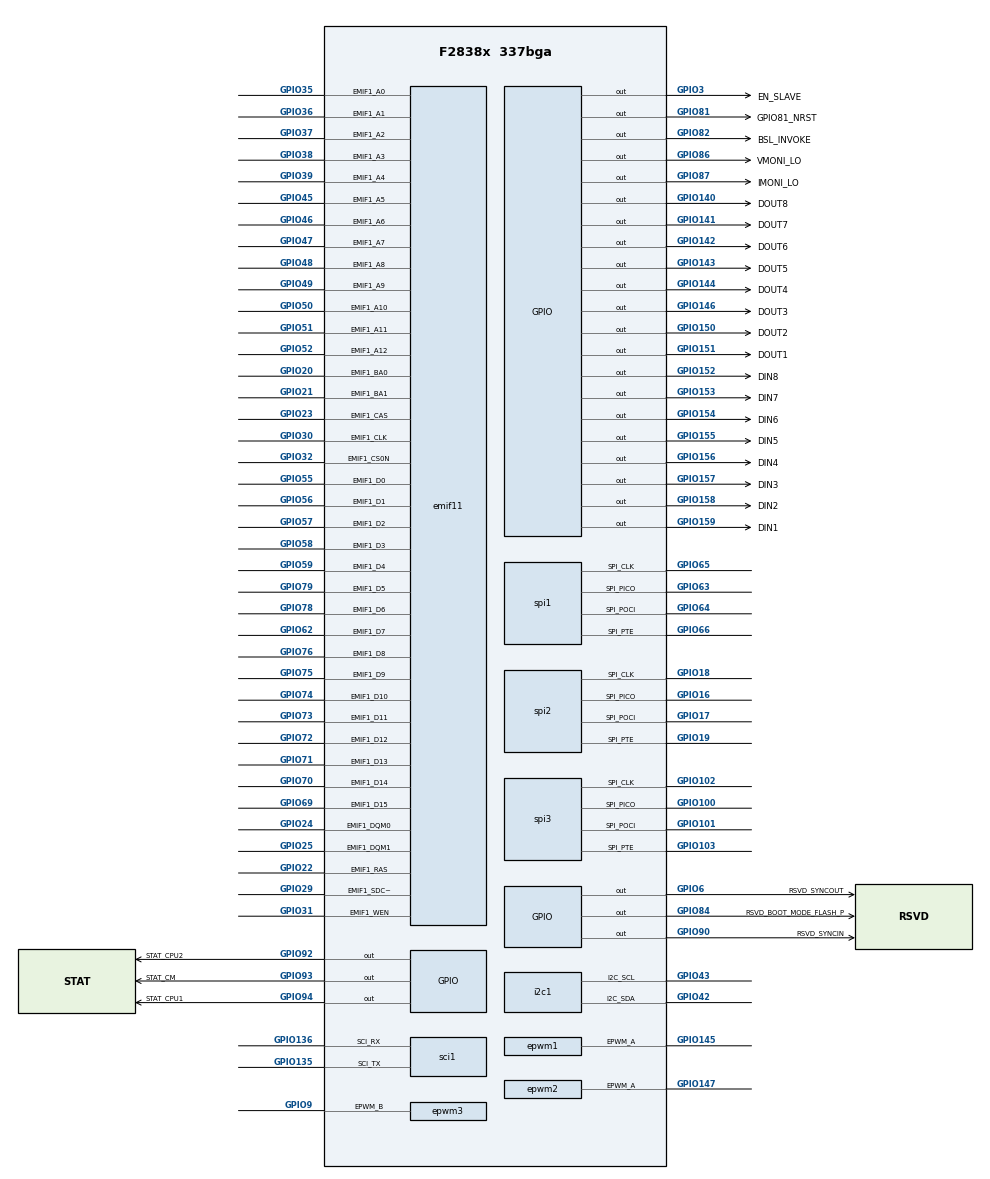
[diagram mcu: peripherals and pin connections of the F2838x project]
/**
 * @cliArgs --device "F2838x" --part "F2838x_337bga" --package "337bga" --context "CPU1" --product "C2000WARE@5.04.00.00"
 * @versions {"tool":"1.21.0+3721"}
 */

/**
 * Import the modules used in this configuration.
 */
const adc              = scripting.addModule("/driverlib/adc.js");
const adc1             = adc.addInstance();
const adc2             = adc.addInstance();
const adc3             = adc.addInstance();
const adc4             = adc.addInstance();
const cputimer         = scripting.addModule("/driverlib/cputimer.js", {}, false);
const cputimer1        = cputimer.addInstance();
const dac              = scripting.addModule("/driverlib/dac.js", {}, false);
const dac1             = dac.addInstance();
const dac2             = dac.addInstance();
const dac3             = dac.addInstance();
const dma              = scripting.addModule("/driverlib/dma.js", {}, false);
const dma1             = dma.addInstance();
const dma2             = dma.addInstance();
const dma3             = dma.addInstance();
const dma4             = dma.addInstance();
const dma5             = dma.addInstance();
const dma6             = dma.addInstance();
const ecap             = scripting.addModule("/driverlib/ecap.js", {}, false);
const ecap1            = ecap.addInstance();
const emif1            = scripting.addModule("/driverlib/emif1.js", {}, false);
const emif11           = emif1.addInstance();
const epwm             = scripting.addModule("/driverlib/epwm.js", {}, false);
const epwm1            = epwm.addInstance();
const epwm2            = epwm.addInstance();
const epwm3            = epwm.addInstance();
const flash            = scripting.addModule("/driverlib/flash.js", {}, false);
const flash1           = flash.addInstance();
const gpio             = scripting.addModule("/driverlib/gpio.js", {}, false);
const gpio1            = gpio.addInstance();
const gpio2            = gpio.addInstance();
const gpio3            = gpio.addInstance();
const gpio4            = gpio.addInstance();
const gpio5            = gpio.addInstance();
const gpio6            = gpio.addInstance();
const gpio7            = gpio.addInstance();
const gpio8            = gpio.addInstance();
const gpio9            = gpio.addInstance();
const gpio10           = gpio.addInstance();
const gpio11           = gpio.addInstance();
const gpio12           = gpio.addInstance();
const gpio13           = gpio.addInstance();
const gpio14           = gpio.addInstance();
const gpio15           = gpio.addInstance();
const gpio16           = gpio.addInstance();
const gpio17           = gpio.addInstance();
const gpio18           = gpio.addInstance();
const gpio19           = gpio.addInstance();
const gpio20           = gpio.addInstance();
const gpio21           = gpio.addInstance();
const gpio22           = gpio.addInstance();
const gpio23           = gpio.addInstance();
const gpio24           = gpio.addInstance();
const gpio25           = gpio.addInstance();
const gpio26           = gpio.addInstance();
const gpio27           = gpio.addInstance();
const i2c              = scripting.addModule("/driverlib/i2c.js", {}, false);
const i2c1             = i2c.addInstance();
const inputxbar_input  = scripting.addModule("/driverlib/inputxbar_input.js", {}, false);
const inputxbar_input1 = inputxbar_input.addInstance();
const ipc              = scripting.addModule("/driverlib/ipc.js");
const sci              = scripting.addModule("/driverlib/sci.js", {}, false);
const sci1             = sci.addInstance();
const spi              = scripting.addModule("/driverlib/spi.js", {}, false);
const spi1             = spi.addInstance();
const spi2             = spi.addInstance();
const spi3             = spi.addInstance();
const sync             = scripting.addModule("/driverlib/sync.js");

/**
 * Write custom configuration values to the imported modules.
 */
adc.synchronousModeCheck = true;

adc1.$name                    = "ADCA_AIN1";
adc1.soc0Channel              = "ADC_CH_ADCIN4";
adc1.adcClockPrescaler        = "ADC_CLK_DIV_4_0";
adc1.soc0SampleWindow         = 64;
adc1.enabledSOCs              = ["ADC_SOC_NUMBER0","ADC_SOC_NUMBER1","ADC_SOC_NUMBER2","ADC_SOC_NUMBER3"];
adc1.soc1SampleWindow         = 64;
adc1.soc0Trigger              = "ADC_TRIGGER_EPWM1_SOCA";
adc1.soc1Trigger              = "ADC_TRIGGER_EPWM1_SOCA";
adc1.soc2Trigger              = "ADC_TRIGGER_EPWM1_SOCA";
adc1.soc2SampleWindow         = 64;
adc1.soc3SampleWindow         = 64;
adc1.soc3Trigger              = "ADC_TRIGGER_EPWM1_SOCA";
adc1.interruptPulseMode       = "ADC_PULSE_END_OF_CONV";
adc1.enabledInts              = ["ADC_INT_NUMBER1"];
adc1.enableInterrupt1         = true;
adc1.interrupt1SOCSource      = "ADC_SOC_NUMBER3";
adc1.registerInterrupts       = ["1"];
adc1.adcInt1.interruptHandler = "INT_CPU1_ADCA_1_ISR";
adc1.adcInt1.enableInterrupt  = true;

adc2.$name             = "ADCB_AIN2";
adc2.adcBase           = "ADCB_BASE";
adc2.adcClockPrescaler = "ADC_CLK_DIV_4_0";
adc2.soc0Channel       = "ADC_CH_ADCIN4";
adc2.soc0Trigger       = "ADC_TRIGGER_EPWM1_SOCA";
adc2.soc0SampleWindow  = 64;
adc2.enabledSOCs       = ["ADC_SOC_NUMBER0","ADC_SOC_NUMBER1","ADC_SOC_NUMBER2","ADC_SOC_NUMBER3"];
adc2.soc1Channel       = "ADC_CH_ADCIN4";
adc2.soc1SampleWindow  = 64;
adc2.soc1Trigger       = "ADC_TRIGGER_EPWM1_SOCA";
adc2.soc2Channel       = "ADC_CH_ADCIN4";
adc2.soc2Trigger       = "ADC_TRIGGER_EPWM1_SOCA";
adc2.soc2SampleWindow  = 64;
adc2.soc3Trigger       = "ADC_TRIGGER_EPWM1_SOCA";
adc2.soc3SampleWindow  = 64;
adc2.soc3Channel       = "ADC_CH_ADCIN4";

adc3.$name             = "ADCC_AIN3";
adc3.adcBase           = "ADCC_BASE";
adc3.adcClockPrescaler = "ADC_CLK_DIV_4_0";
adc3.soc0Channel       = "ADC_CH_ADCIN4";
adc3.enabledSOCs       = ["ADC_SOC_NUMBER0","ADC_SOC_NUMBER1","ADC_SOC_NUMBER2","ADC_SOC_NUMBER3"];
adc3.soc0Trigger       = "ADC_TRIGGER_EPWM1_SOCA";
adc3.soc0SampleWindow  = 64;
adc3.soc1Channel       = "ADC_CH_ADCIN4";
adc3.soc1Trigger       = "ADC_TRIGGER_EPWM1_SOCA";
adc3.soc1SampleWindow  = 64;
adc3.soc2Trigger       = "ADC_TRIGGER_EPWM1_SOCA";
adc3.soc2SampleWindow  = 64;
adc3.soc2Channel       = "ADC_CH_ADCIN4";
adc3.soc3Channel       = "ADC_CH_ADCIN4";
adc3.soc3SampleWindow  = 64;
adc3.soc3Trigger       = "ADC_TRIGGER_EPWM1_SOCA";

adc4.$name             = "RSVD_ADCD";
adc4.adcBase           = "ADCD_BASE";
adc4.adcClockPrescaler = "ADC_CLK_DIV_4_0";
adc4.soc0Channel       = "ADC_CH_ADCIN4";
adc4.enabledSOCs       = ["ADC_SOC_NUMBER0","ADC_SOC_NUMBER1","ADC_SOC_NUMBER2","ADC_SOC_NUMBER3"];
adc4.soc0SampleWindow  = 64;
adc4.soc0Trigger       = "ADC_TRIGGER_EPWM1_SOCA";
adc4.soc1Channel       = "ADC_CH_ADCIN4";
adc4.soc1Trigger       = "ADC_TRIGGER_EPWM1_SOCA";
adc4.soc1SampleWindow  = 64;
adc4.soc2Channel       = "ADC_CH_ADCIN4";
adc4.soc2SampleWindow  = 64;
adc4.soc2Trigger       = "ADC_TRIGGER_EPWM1_SOCA";
adc4.soc3Channel       = "ADC_CH_ADCIN4";
adc4.soc3Trigger       = "ADC_TRIGGER_EPWM1_SOCA";
adc4.soc3SampleWindow  = 64;

const divider11       = system.clockTree["LOSPCP"];
divider11.divideValue = 1;

cputimer1.emulationMode  = "CPUTIMER_EMULATIONMODE_RUNFREE";
cputimer1.timerPrescaler = 3;
cputimer1.timerPeriod    = 50000000;
cputimer1.startTimer     = true;
cputimer1.$name          = "SWTIRMER";

dac1.$name = "DACA_AOUT1";

dac2.$name   = "DACB_AOUT2";
dac2.dacBase = "DACB_BASE";

dac3.$name            = "RSVD_DACC";
dac3.dacBase          = "DACC_BASE";
dac3.enableOutput     = true;
dac3.referenceVoltage = "DAC_REF_ADC_VREFHI";

dma1.$name = "DMA_SPIC_TX";

dma2.$name   = "DMA_SPIC_RX";
dma2.dmaBase = "DMA_CH2_BASE";

dma3.$name   = "DMA_SPIB_TX";
dma3.dmaBase = "DMA_CH3_BASE";

dma4.$name   = "DMA_SPIB_RX";
dma4.dmaBase = "DMA_CH4_BASE";

dma5.$name   = "DMA_SPIA_TX";
dma5.dmaBase = "DMA_CH5_BASE";

dma6.$name   = "DMA_SPIA_RX";
dma6.dmaBase = "DMA_CH6_BASE";

ecap1.ecapInput = "ECAP_INPUT_GPIO8";
ecap1.$name     = "ECAP1_ACFAIL";

emif11.enableCS3                    = false;
emif11.enableCS4                    = false;
emif11.useCase                      = "CUSTOM";
emif11.useInterfacePins             = ["EMIF1_A0","EMIF1_A1","EMIF1_A10","EMIF1_A11","EMIF1_A12","EMIF1_A2","EMIF1_A3","EMIF1_A4","EMIF1_A5","EMIF1_A6","EMIF1_A7","EMIF1_A8","EMIF1_A9","EMIF1_BA0","EMIF1_BA1","EMIF1_CAS","EMIF1_CLK","EMIF1_CS0n","EMIF1_D0","EMIF1_D1","EMIF1_D10","EMIF1_D11","EMIF1_D12","EMIF1_D13","EMIF1_D14","EMIF1_D15","EMIF1_D2","EMIF1_D3","EMIF1_D4","EMIF1_D5","EMIF1_D6","EMIF1_D7","EMIF1_D8","EMIF1_D9","EMIF1_DQM0","EMIF1_DQM1","EMIF1_RAS","EMIF1_SDCKE","EMIF1_WEn"];
emif11.cs0Narrow                    = "EMIF_SYNC_NARROW_MODE_TRUE";
emif11.enableCS2                    = false;
emif11.$name                        = "EMIF1_SDRAM";
emif11.emif1.$assign                = "EMIF1";
emif11.emif1.emif1_cs0nPin.$assign  = "GPIO32";
emif11.emif1.emif1_sdckePin.$assign = "GPIO29";
emif11.emif1.emif1_clkPin.$assign   = "GPIO30";
emif11.emif1.emif1_wenPin.$assign   = "GPIO31";
emif11.emif1.emif1_casPin.$assign   = "GPIO23";
emif11.emif1.emif1_rasPin.$assign   = "GPIO22";
emif11.emif1.emif1_dqm0Pin.$assign  = "GPIO24";
emif11.emif1.emif1_dqm1Pin.$assign  = "GPIO25";
emif11.emif1.emif1_ba0Pin.$assign   = "GPIO20";
emif11.emif1.emif1_ba1Pin.$assign   = "GPIO21";
emif11.emif1.emif1_a0Pin.$assign    = "GPIO35";
emif11.emif1.emif1_a1Pin.$assign    = "GPIO36";
emif11.emif1.emif1_a2Pin.$assign    = "GPIO37";
emif11.emif1.emif1_a3Pin.$assign    = "GPIO38";
emif11.emif1.emif1_a4Pin.$assign    = "GPIO39";
emif11.emif1.emif1_a5Pin.$assign    = "GPIO45";
emif11.emif1.emif1_a6Pin.$assign    = "GPIO46";
emif11.emif1.emif1_a7Pin.$assign    = "GPIO47";
emif11.emif1.emif1_a8Pin.$assign    = "GPIO48";
emif11.emif1.emif1_a9Pin.$assign    = "GPIO49";
emif11.emif1.emif1_a10Pin.$assign   = "GPIO50";
emif11.emif1.emif1_a11Pin.$assign   = "GPIO51";
emif11.emif1.emif1_a12Pin.$assign   = "GPIO52";
emif11.emif1.emif1_d0Pin.$assign    = "GPIO55";
emif11.emif1.emif1_d1Pin.$assign    = "GPIO56";
emif11.emif1.emif1_d2Pin.$assign    = "GPIO57";
emif11.emif1.emif1_d3Pin.$assign    = "GPIO58";
emif11.emif1.emif1_d4Pin.$assign    = "GPIO59";
emif11.emif1.emif1_d5Pin.$assign    = "GPIO79";
emif11.emif1.emif1_d6Pin.$assign    = "GPIO78";
emif11.emif1.emif1_d7Pin.$assign    = "GPIO62";
emif11.emif1.emif1_d8Pin.$assign    = "GPIO76";
emif11.emif1.emif1_d9Pin.$assign    = "GPIO75";
emif11.emif1.emif1_d10Pin.$assign   = "GPIO74";
emif11.emif1.emif1_d11Pin.$assign   = "GPIO73";
emif11.emif1.emif1_d12Pin.$assign   = "GPIO72";
emif11.emif1.emif1_d13Pin.$assign   = "GPIO71";
emif11.emif1.emif1_d14Pin.$assign   = "GPIO70";
emif11.emif1.emif1_d15Pin.$assign   = "GPIO69";

epwm1.useCase                = "CUSTOM";
epwm1.useInterfacePins       = ["EPWM#A"];
epwm1.$name                  = "MEAS_CNV";
epwm1.epwm.$assign           = "EPWM1";
epwm1.epwm.epwm_aPin.$assign = "GPIO145";

epwm2.useCase                = "CUSTOM";
epwm2.useInterfacePins       = ["EPWM#A"];
epwm2.$name                  = "CVAD_CNV";
epwm2.epwm.$assign           = "EPWM2";
epwm2.epwm.epwm_aPin.$assign = "GPIO147";

epwm3.$name                  = "PWM5_OFFPWM";
epwm3.useCase                = "CUSTOM";
epwm3.useInterfacePins       = ["EPWM#B"];
epwm3.epwm.$assign           = "EPWM5";
epwm3.epwm.epwm_bPin.$assign = "GPIO9";

flash1.$name = "FMC_CPU1";

gpio1.$name           = "RSVD_BOOT_MODE_FLASH_P";
gpio1.gpioPin.$assign = "GPIO84";

gpio2.$name           = "RSVD_SYNCIN";
gpio2.gpioPin.$assign = "GPIO90";

gpio3.$name           = "RSVD_SYNCOUT";
gpio3.gpioPin.$assign = "GPIO6";

gpio4.$name           = "DIN1";
gpio4.gpioPin.$assign = "GPIO159";

gpio5.$name           = "DIN2";
gpio5.gpioPin.$assign = "GPIO158";

gpio6.$name           = "DIN3";
gpio6.gpioPin.$assign = "GPIO157";

gpio7.$name           = "DIN4";
gpio7.gpioPin.$assign = "GPIO156";

gpio8.$name           = "DIN5";
gpio8.gpioPin.$assign = "GPIO155";

gpio9.$name           = "DIN6";
gpio9.gpioPin.$assign = "GPIO154";

gpio10.$name           = "DIN7";
gpio10.gpioPin.$assign = "GPIO153";

gpio11.$name           = "DIN8";
gpio11.gpioPin.$assign = "GPIO152";

gpio12.$name           = "DOUT1";
gpio12.direction       = "GPIO_DIR_MODE_OUT";
gpio12.gpioPin.$assign = "GPIO151";

gpio13.$name           = "DOUT2";
gpio13.direction       = "GPIO_DIR_MODE_OUT";
gpio13.gpioPin.$assign = "GPIO150";

gpio14.$name           = "DOUT3";
gpio14.direction       = "GPIO_DIR_MODE_OUT";
gpio14.gpioPin.$assign = "GPIO146";

gpio15.$name           = "DOUT4";
gpio15.direction       = "GPIO_DIR_MODE_OUT";
gpio15.gpioPin.$assign = "GPIO144";

gpio16.$name           = "DOUT5";
gpio16.direction       = "GPIO_DIR_MODE_OUT";
gpio16.gpioPin.$assign = "GPIO143";

gpio17.$name           = "DOUT6";
gpio17.direction       = "GPIO_DIR_MODE_OUT";
gpio17.gpioPin.$assign = "GPIO142";

gpio18.$name           = "DOUT7";
gpio18.gpioPin.$assign = "GPIO141";

gpio19.$name           = "DOUT8";
gpio19.direction       = "GPIO_DIR_MODE_OUT";
gpio19.gpioPin.$assign = "GPIO140";

gpio20.direction         = "GPIO_DIR_MODE_OUT";
gpio20.$name             = "EN_SLAVE";
gpio20.writeInitialValue = true;
gpio20.gpioPin.$assign   = "GPIO3";

gpio21.$name             = "VMONI_LO";
gpio21.direction         = "GPIO_DIR_MODE_OUT";
gpio21.writeInitialValue = true;
gpio21.gpioPin.$assign   = "GPIO86";

gpio22.$name             = "IMONI_LO";
gpio22.direction         = "GPIO_DIR_MODE_OUT";
gpio22.writeInitialValue = true;
gpio22.gpioPin.$assign   = "GPIO87";

gpio23.$name           = "STAT_CPU1";
gpio23.gpioPin.$assign = "GPIO94";

gpio24.$name           = "STAT_CPU2";
gpio24.direction       = "GPIO_DIR_MODE_OUT";
gpio24.controllerCore  = "GPIO_CORE_CPU2";
gpio24.gpioPin.$assign = "GPIO92";

gpio25.$name           = "STAT_CM";
gpio25.direction       = "GPIO_DIR_MODE_OUT";
gpio25.gpioPin.$assign = "GPIO93";

gpio26.$name           = "BSL_INVOKE";
gpio26.direction       = "GPIO_DIR_MODE_OUT";
gpio26.gpioPin.$assign = "GPIO82";

gpio27.$name           = "GPIO81_NRST";
gpio27.gpioPin.$assign = "GPIO81";

i2c1.$name                  = "I2CA_M";
i2c1.i2c.$assign            = "I2CA";
i2c1.i2c.i2c_sdaPin.$assign = "GPIO42";
i2c1.i2c.i2c_sclPin.$assign = "GPIO43";

inputxbar_input1.$name         = "myINPUTXBARINPUT0";
inputxbar_input1.inputxbarGpio = "GPIO90";

ipc.ipcRegisterFlag = ["IPC_FLAG31"];

sci1.$name                 = "SCI_BOOT_DEBUG";
sci1.sci.$assign           = "SCIA";
sci1.sci.sci_rxPin.$assign = "GPIO136";
sci1.sci.sci_txPin.$assign = "GPIO135";
sci1.rxQual.$name          = "myGPIOQUAL18";
sci1.txQual.$name          = "myGPIOQUAL19";

spi1.useHSMode               = true;
spi1.bitRate                 = 50000000;
spi1.$name                   = "SPIB_SYSTEM";
spi1.spi.$assign             = "SPIB";
spi1.spi.spi_picoPin.$assign = "GPIO63";
spi1.spi.spi_pociPin.$assign = "GPIO64";
spi1.spi.spi_clkPin.$assign  = "GPIO65";
spi1.spi.spi_ptePin.$assign  = "GPIO66";
spi1.picoQual.$name          = "myGPIOQUAL6";
spi1.pociQual.$name          = "myGPIOQUAL7";
spi1.clkQual.$name           = "myGPIOQUAL8";
spi1.pteQual.$name           = "myGPIOQUAL9";

spi2.bitRate                 = 10000000;
spi2.$name                   = "SPIA_EXTFLASH";
spi2.spi.$assign             = "SPIA";
spi2.spi.spi_picoPin.$assign = "GPIO16";
spi2.spi.spi_pociPin.$assign = "GPIO17";
spi2.spi.spi_clkPin.$assign  = "GPIO18";
spi2.spi.spi_ptePin.$assign  = "GPIO19";
spi2.picoQual.$name          = "myGPIOQUAL10";
spi2.pociQual.$name          = "myGPIOQUAL11";
spi2.clkQual.$name           = "myGPIOQUAL12";
spi2.pteQual.$name           = "myGPIOQUAL13";

spi3.$name                   = "SPIC_MEAS_DDS";
spi3.bitRate                 = 10000000;
spi3.spi.$assign             = "SPIC";
spi3.spi.spi_picoPin.$assign = "GPIO100";
spi3.spi.spi_pociPin.$assign = "GPIO101";
spi3.spi.spi_clkPin.$assign  = "GPIO102";
spi3.spi.spi_ptePin.$assign  = "GPIO103";
spi3.picoQual.$name          = "myGPIOQUAL0";
spi3.pociQual.$name          = "myGPIOQUAL1";
spi3.clkQual.$name           = "myGPIOQUAL2";
spi3.pteQual.$name           = "myGPIOQUAL3";

sync.syncOutLock = true;
